# ESP32-P4 register map
Vendor: ESPRESSIF SYSTEMS (SHANGHAI) CO., LTD.; Series: ESP32 P-Series; File version: 3
CPU: RV32IMAFC r0p0, little endian, no MPU, FPU, 0 interrupt priority bits
Address unit: 32 bits
Registers are 32-bit, read-write, reset 0x0 unless marked. A register's access mark holds for its fields unless they carry their own. Offsets are from the block's base; [hi:lo] are bit positions; {n}, {i} and the like mark numbered series; <NAME> marks a mode.

## AXI_DMA — AXI_DMA Peripheral
Base 0x5008A000
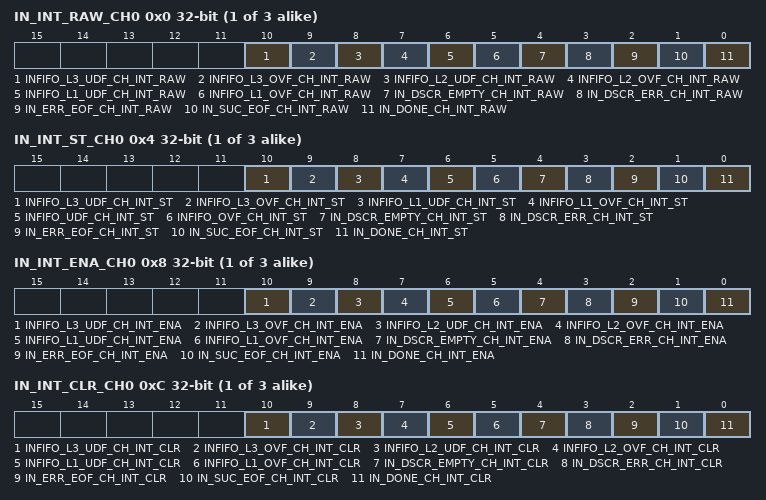
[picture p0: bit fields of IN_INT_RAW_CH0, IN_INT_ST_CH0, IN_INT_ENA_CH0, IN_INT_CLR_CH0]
{0x0+0x68*i} IN_INT_RAW_CH{i} (i=0..2) — Raw status interrupt of channel {i}
  [10] INFIFO_L3_UDF_CH_INT_RAW — This raw interrupt bit turns to high level when level 1 fifo of Rx channel 0 is underflow.
  [9] INFIFO_L3_OVF_CH_INT_RAW — This raw interrupt bit turns to high level when level 1 fifo of Rx channel 0 is overflow.
  [8] INFIFO_L2_UDF_CH_INT_RAW — This raw interrupt bit turns to high level when level 1 fifo of Rx channel 0 is underflow.
  [7] INFIFO_L2_OVF_CH_INT_RAW — This raw interrupt bit turns to high level when level 1 fifo of Rx channel 0 is overflow.
  [6] INFIFO_L1_UDF_CH_INT_RAW — This raw interrupt bit turns to high level when level 1 fifo of Rx channel 0 is underflow.
  [5] INFIFO_L1_OVF_CH_INT_RAW — This raw interrupt bit turns to high level when level 1 fifo of Rx channel 0 is overflow.
  [4] IN_DSCR_EMPTY_CH_INT_RAW — The raw interrupt bit turns to high level when Rx buffer pointed by inlink is full and receiving data is not completed but there is no more inlink for Rx channel 0.
  [3] IN_DSCR_ERR_CH_INT_RAW — The raw interrupt bit turns to high level when detecting inlink descriptor error including owner error and the second and third word error of inlink descriptor for Rx channel 0.
  [2] IN_ERR_EOF_CH_INT_RAW — The raw interrupt bit turns to high level when data error is detected only in the case that the peripheral is UHCI0 for Rx channel 0. For other peripherals this raw interrupt is reserved.
  [1] IN_SUC_EOF_CH_INT_RAW — The raw interrupt bit turns to high level when the last data pointed by one inlink descriptor has been received for Rx channel 0. For UHCI0 the raw interrupt bit turns to high level when the last data pointed by one inlink descriptor has been received and no data error is detected for Rx channel 0.
  [0] IN_DONE_CH_INT_RAW — The raw interrupt bit turns to high level when the last data pointed by one inlink descriptor has been received for Rx channel 0.
{0x4+0x68*i} IN_INT_ST_CH{i} (i=0..2) ro — Masked interrupt of channel {i}
  [10] INFIFO_L3_UDF_CH_INT_ST — The raw interrupt status bit for the INFIFO_UDF_L3_CH_INT interrupt.
  [9] INFIFO_L3_OVF_CH_INT_ST — The raw interrupt status bit for the INFIFO_OVF_L3_CH_INT interrupt.
  [8] INFIFO_L1_UDF_CH_INT_ST — The raw interrupt status bit for the INFIFO_UDF_L2_CH_INT interrupt.
  [7] INFIFO_L1_OVF_CH_INT_ST — The raw interrupt status bit for the INFIFO_OVF_L2_CH_INT interrupt.
  [6] INFIFO_UDF_CH_INT_ST — The raw interrupt status bit for the INFIFO_UDF_L1_CH_INT interrupt.
  [5] INFIFO_OVF_CH_INT_ST — The raw interrupt status bit for the INFIFO_OVF_L1_CH_INT interrupt.
  [4] IN_DSCR_EMPTY_CH_INT_ST — The raw interrupt status bit for the IN_DSCR_EMPTY_CH_INT interrupt.
  [3] IN_DSCR_ERR_CH_INT_ST — The raw interrupt status bit for the IN_DSCR_ERR_CH_INT interrupt.
  [2] IN_ERR_EOF_CH_INT_ST — The raw interrupt status bit for the IN_ERR_EOF_CH_INT interrupt.
  [1] IN_SUC_EOF_CH_INT_ST — The raw interrupt status bit for the IN_SUC_EOF_CH_INT interrupt.
  [0] IN_DONE_CH_INT_ST — The raw interrupt status bit for the IN_DONE_CH_INT interrupt.
{0x8+0x68*i} IN_INT_ENA_CH{i} (i=0..2) — Interrupt enable bits of channel {i}
  [10] INFIFO_L3_UDF_CH_INT_ENA — The interrupt enable bit for the INFIFO_UDF_L3_CH_INT interrupt.
  [9] INFIFO_L3_OVF_CH_INT_ENA — The interrupt enable bit for the INFIFO_OVF_L3_CH_INT interrupt.
  [8] INFIFO_L2_UDF_CH_INT_ENA — The interrupt enable bit for the INFIFO_UDF_L2_CH_INT interrupt.
  [7] INFIFO_L2_OVF_CH_INT_ENA — The interrupt enable bit for the INFIFO_OVF_L2_CH_INT interrupt.
  [6] INFIFO_L1_UDF_CH_INT_ENA — The interrupt enable bit for the INFIFO_UDF_L1_CH_INT interrupt.
  [5] INFIFO_L1_OVF_CH_INT_ENA — The interrupt enable bit for the INFIFO_OVF_L1_CH_INT interrupt.
  [4] IN_DSCR_EMPTY_CH_INT_ENA — The interrupt enable bit for the IN_DSCR_EMPTY_CH_INT interrupt.
  [3] IN_DSCR_ERR_CH_INT_ENA — The interrupt enable bit for the IN_DSCR_ERR_CH_INT interrupt.
  [2] IN_ERR_EOF_CH_INT_ENA — The interrupt enable bit for the IN_ERR_EOF_CH_INT interrupt.
  [1] IN_SUC_EOF_CH_INT_ENA — The interrupt enable bit for the IN_SUC_EOF_CH_INT interrupt.
  [0] IN_DONE_CH_INT_ENA — The interrupt enable bit for the IN_DONE_CH_INT interrupt.
{0xC+0x68*i} IN_INT_CLR_CH{i} (i=0..2) wo — Interrupt clear bits of channel {i}
  [10] INFIFO_L3_UDF_CH_INT_CLR — Set this bit to clear the INFIFO_UDF_L3_CH_INT interrupt.
  [9] INFIFO_L3_OVF_CH_INT_CLR — Set this bit to clear the INFIFO_OVF_L3_CH_INT interrupt.
  [8] INFIFO_L2_UDF_CH_INT_CLR — Set this bit to clear the INFIFO_UDF_L2_CH_INT interrupt.
  [7] INFIFO_L2_OVF_CH_INT_CLR — Set this bit to clear the INFIFO_OVF_L2_CH_INT interrupt.
  [6] INFIFO_L1_UDF_CH_INT_CLR — Set this bit to clear the INFIFO_UDF_L1_CH_INT interrupt.
  [5] INFIFO_L1_OVF_CH_INT_CLR — Set this bit to clear the INFIFO_OVF_L1_CH_INT interrupt.
  [4] IN_DSCR_EMPTY_CH_INT_CLR — Set this bit to clear the IN_DSCR_EMPTY_CH_INT interrupt.
  [3] IN_DSCR_ERR_CH_INT_CLR — Set this bit to clear the IN_DSCR_ERR_CH_INT interrupt.
  [2] IN_ERR_EOF_CH_INT_CLR — Set this bit to clear the IN_ERR_EOF_CH_INT interrupt.
  [1] IN_SUC_EOF_CH_INT_CLR — Set this bit to clear the IN_SUC_EOF_CH_INT interrupt.
  [0] IN_DONE_CH_INT_CLR — Set this bit to clear the IN_DONE_CH_INT interrupt.
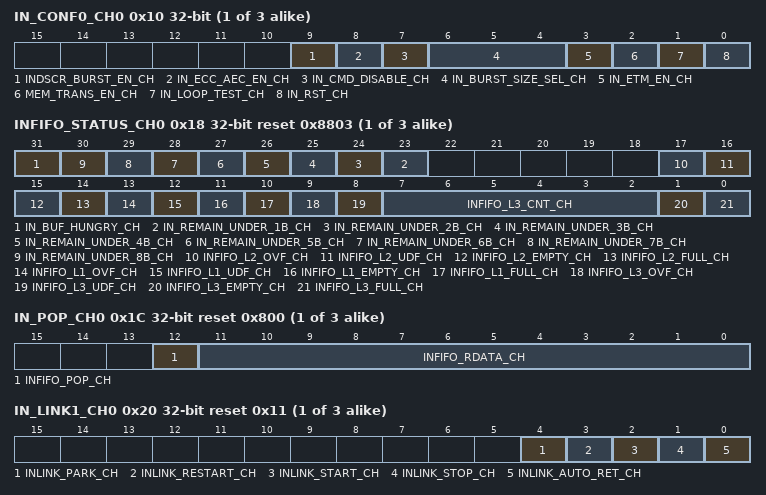
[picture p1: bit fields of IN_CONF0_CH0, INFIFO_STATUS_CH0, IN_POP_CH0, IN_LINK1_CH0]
{0x10+0x68*i} IN_CONF0_CH{i} (i=0..2) — Configure 0 register of Rx channel {i}
  [9] INDSCR_BURST_EN_CH — Set this bit to 1 to enable INCR burst transfer for Rx channel 0 reading link descriptor when accessing internal SRAM.
  [8] IN_ECC_AEC_EN_CH — 1: mean access ecc or aes domain,0: mean not
  [7] IN_CMD_DISABLE_CH — 1:mean disable cmd of this ch0
  [6:4] IN_BURST_SIZE_SEL_CH — 3'b000-3'b100:burst length 8byte~128byte
  [3] IN_ETM_EN_CH — Set this bit to 1 to enable etm control mode, dma Rx channel 0 is triggered by etm task.
  [2] MEM_TRANS_EN_CH — Set this bit 1 to enable automatic transmitting data from memory to memory via AXI_DMA.
  [1] IN_LOOP_TEST_CH — reserved
  [0] IN_RST_CH — This bit is used to reset AXI_DMA channel 0 Rx FSM and Rx FIFO pointer.
{0x14+0x68*i} IN_CONF1_CH{i} (i=0..2) — Configure 1 register of Rx channel {i}
  [12] IN_CHECK_OWNER_CH — Set this bit to enable checking the owner attribute of the link descriptor.
{0x18+0x68*i} INFIFO_STATUS_CH{i} (i=0..2) ro reset 0x8803 — Receive FIFO status of Rx channel {i}
  [31] IN_BUF_HUNGRY_CH — reserved
  [n+22] IN_REMAIN_UNDER_{n}B_CH (n=1..8) — reserved
  [17] INFIFO_L2_OVF_CH — L2 Rx FIFO over flow signal for Rx channel 0.
  [16] INFIFO_L2_UDF_CH — L2 Rx FIFO under flow signal for Rx channel 0.
  [15] INFIFO_L2_EMPTY_CH — L2 Rx RAM empty signal for Rx channel 0.
  [14] INFIFO_L2_FULL_CH — L2 Rx RAM full signal for Rx channel 0.
  [13] INFIFO_L1_OVF_CH — L1 Rx FIFO over flow signal for Rx channel 0.
  [12] INFIFO_L1_UDF_CH — L1 Rx FIFO under flow signal for Rx channel 0.
  [11] INFIFO_L1_EMPTY_CH — L1 Rx FIFO empty signal for Rx channel 0.
  [10] INFIFO_L1_FULL_CH — L1 Rx FIFO full signal for Rx channel 0.
  [9] INFIFO_L3_OVF_CH — L3 Rx FIFO over flow signal for Rx channel 0.
  [8] INFIFO_L3_UDF_CH — L3 Rx FIFO under flow signal for Rx channel 0.
  [7:2] INFIFO_L3_CNT_CH — The register stores the byte number of the data in L3 Rx FIFO for Rx channel 0.
  [1] INFIFO_L3_EMPTY_CH — L3 Rx FIFO empty signal for Rx channel 0.
  [0] INFIFO_L3_FULL_CH — L3 Rx FIFO full signal for Rx channel 0.
{0x1C+0x68*i} IN_POP_CH{i} (i=0..2) access per field reset 0x800 — Pop control register of Rx channel {i}
  [12] INFIFO_POP_CH wo — Set this bit to pop data from AXI_DMA FIFO.
  [11:0] INFIFO_RDATA_CH ro — This register stores the data popping from AXI_DMA FIFO.
{0x20+0x68*i} IN_LINK1_CH{i} (i=0..2) access per field reset 0x11 — Link descriptor configure and control register of Rx channel {i}
  [4] INLINK_PARK_CH ro — 1: the inlink descriptor's FSM is in idle state. 0: the inlink descriptor's FSM is working.
  [3] INLINK_RESTART_CH wo — Set this bit to mount a new inlink descriptor.
  [2] INLINK_START_CH wo — Set this bit to start dealing with the inlink descriptors.
  [1] INLINK_STOP_CH wo — Set this bit to stop dealing with the inlink descriptors.
  [0] INLINK_AUTO_RET_CH rw — Set this bit to return to current inlink descriptor's address when there are some errors in current receiving data.
{0x24+0x68*i} IN_LINK2_CH{i} (i=0..2) — Link descriptor configure and control register of Rx channel {i}
  [31:0] INLINK_ADDR_CH — This register stores the 20 least significant bits of the first inlink descriptor's address.
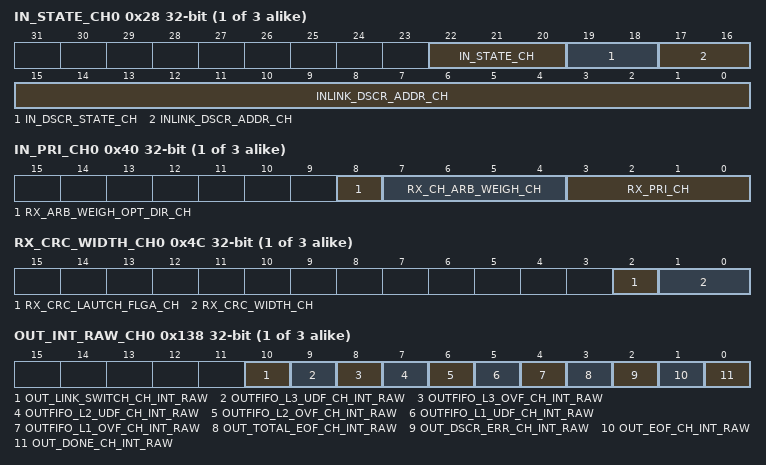
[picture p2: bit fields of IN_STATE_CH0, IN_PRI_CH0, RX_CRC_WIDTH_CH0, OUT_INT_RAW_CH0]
{0x28+0x68*i} IN_STATE_CH{i} (i=0..2) ro — Receive status of Rx channel {i}
  [22:20] IN_STATE_CH — reserved
  [19:18] IN_DSCR_STATE_CH — reserved
  [17:0] INLINK_DSCR_ADDR_CH — This register stores the current inlink descriptor's address.
{0x2C+0x68*i} IN_SUC_EOF_DES_ADDR_CH{i} (i=0..2) ro — Inlink descriptor address when EOF occurs of Rx channel {i}
  [31:0] IN_SUC_EOF_DES_ADDR_CH — This register stores the address of the inlink descriptor when the EOF bit in this descriptor is 1.
{0x30+0x68*i} IN_ERR_EOF_DES_ADDR_CH{i} (i=0..2) ro — Inlink descriptor address when errors occur of Rx channel {i}
  [31:0] IN_ERR_EOF_DES_ADDR_CH — This register stores the address of the inlink descriptor when there are some errors in current receiving data. Only used when peripheral is UHCI0.
{0x34+0x68*i} IN_DSCR_CH{i} (i=0..2) ro — Current inlink descriptor address of Rx channel {i}
  [31:0] INLINK_DSCR_CH — The address of the current inlink descriptor x.
{0x38+0x68*i} IN_DSCR_BF0_CH{i} (i=0..2) ro — The last inlink descriptor address of Rx channel {i}
  [31:0] INLINK_DSCR_BF0_CH — The address of the last inlink descriptor x-1.
{0x3C+0x68*i} IN_DSCR_BF1_CH{i} (i=0..2) ro — The second-to-last inlink descriptor address of Rx channel {i}
  [31:0] INLINK_DSCR_BF1_CH — The address of the second-to-last inlink descriptor x-2.
{0x40+0x68*i} IN_PRI_CH{i} (i=0..2) — Priority register of Rx channel {i}
  [8] RX_ARB_WEIGH_OPT_DIR_CH — 0: mean not optimazation weight function ,1: mean optimazation
  [7:4] RX_CH_ARB_WEIGH_CH — The weight of Rx channel 0
  [3:0] RX_PRI_CH — The priority of Rx channel 0. The larger of the value the higher of the priority.
{0x44+0x68*i} IN_PERI_SEL_CH{i} (i=0..2) reset 0x3F — Peripheral selection of Rx channel {i}
  [5:0] PERI_IN_SEL_CH — This register is used to select peripheral for Rx channel 0. 0:lcdcam. 1: gpspi_2. 2: gpspi_3. 3: parl_io. 4: aes. 5: sha. 6~15: Dummy
{0x48+0x68*i} IN_CRC_INIT_DATA_CH{i} (i=0..2) reset 0xFFFFFFFF — This register is used to config ch{i} crc initial data(max 32 bit)
  [31:0] IN_CRC_INIT_DATA_CH — This register is used to config ch0 of rx crc initial value
{0x4C+0x68*i} RX_CRC_WIDTH_CH{i} (i=0..2) — This register is used to confiig rx ch{i} crc result width,2'b00 mean crc_width <=8bit,2'b01 8<crc_width<=16 ,2'b10 mean 16<crc_width <=24,2'b11 mean 24<crc_width<=32
  [2] RX_CRC_LAUTCH_FLGA_CH — reserved
  [1:0] RX_CRC_WIDTH_CH — reserved
{0x50+0x68*i} IN_CRC_CLEAR_CH{i} (i=0..2) — This register is used to clear ch{i} crc result
  [0] IN_CRC_CLEAR_CH — This register is used to clear ch0 of rx crc result
{0x54+0x68*i} IN_CRC_FINAL_RESULT_CH{i} (i=0..2) ro — This register is used to store ch{i} crc result
  [31:0] IN_CRC_FINAL_RESULT_CH — This register is used to store result ch0 of rx
{0x58+0x68*i} RX_CRC_EN_WR_DATA_CH{i} (i=0..2) — This resister is used to config ch{i} crc en for every bit
  [31:0] RX_CRC_EN_WR_DATA_CH — This register is used to enable rx ch0 crc 32bit on/off
{0x5C+0x68*i} RX_CRC_EN_ADDR_CH{i} (i=0..2) — This register is used to config ch{i} crc en addr
  [31:0] RX_CRC_EN_ADDR_CH — reserved
{0x60+0x68*i} RX_CRC_DATA_EN_WR_DATA_CH{i} (i=0..2) — This register is used to config crc data_8bit en
  [15:0] RX_CRC_DATA_EN_WR_DATA_CH — reserved
{0x64+0x68*i} RX_CRC_DATA_EN_ADDR_CH{i} (i=0..2) — This register is used to config addr of crc data_8bit en
  [31:0] RX_CRC_DATA_EN_ADDR_CH — reserved
{0x138+0x68*i} OUT_INT_RAW_CH{i} (i=0..2) — Raw status interrupt of channel{i}
  [10] OUT_LINK_SWITCH_CH_INT_RAW — The raw interrupt bit turns to high level when the dma switch to new link for Tx channel0.
  [9] OUTFIFO_L3_UDF_CH_INT_RAW — This raw interrupt bit turns to high level when level 1 fifo of Tx channel0 is underflow.
  [8] OUTFIFO_L3_OVF_CH_INT_RAW — This raw interrupt bit turns to high level when level 1 fifo of Tx channel0 is overflow.
  [7] OUTFIFO_L2_UDF_CH_INT_RAW — This raw interrupt bit turns to high level when level 1 fifo of Tx channel0 is underflow.
  [6] OUTFIFO_L2_OVF_CH_INT_RAW — This raw interrupt bit turns to high level when level 1 fifo of Tx channel0 is overflow.
  [5] OUTFIFO_L1_UDF_CH_INT_RAW — This raw interrupt bit turns to high level when level 1 fifo of Tx channel0 is underflow.
  [4] OUTFIFO_L1_OVF_CH_INT_RAW — This raw interrupt bit turns to high level when level 1 fifo of Tx channel0 is overflow.
  [3] OUT_TOTAL_EOF_CH_INT_RAW — The raw interrupt bit turns to high level when data corresponding a outlink (includes one link descriptor or few link descriptors) is transmitted out for Tx channel0.
  [2] OUT_DSCR_ERR_CH_INT_RAW — The raw interrupt bit turns to high level when detecting outlink descriptor error including owner error and the second and third word error of outlink descriptor for Tx channel0.
  [1] OUT_EOF_CH_INT_RAW — The raw interrupt bit turns to high level when the last data pointed by one outlink descriptor has been read from memory for Tx channel0.
  [0] OUT_DONE_CH_INT_RAW — The raw interrupt bit turns to high level when the last data pointed by one outlink descriptor has been transmitted to peripherals for Tx channel0.
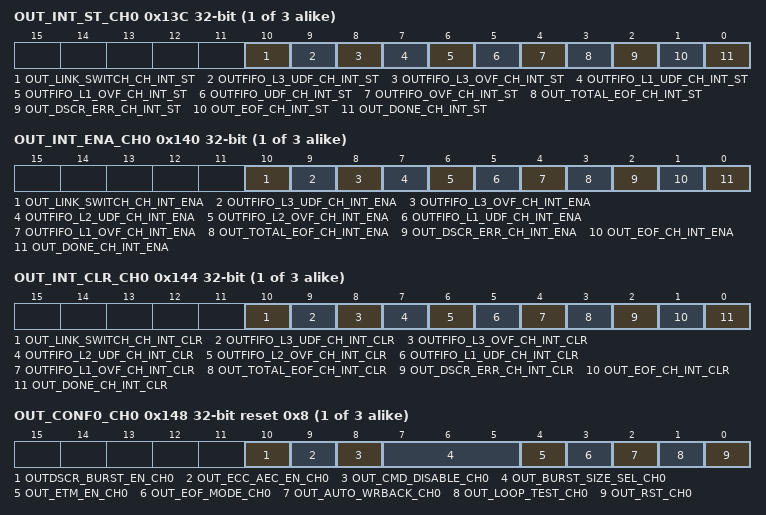
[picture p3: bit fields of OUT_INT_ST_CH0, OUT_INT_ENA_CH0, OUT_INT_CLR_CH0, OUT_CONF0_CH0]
{0x13C+0x68*i} OUT_INT_ST_CH{i} (i=0..2) ro — Masked interrupt of channel{i}
  [10] OUT_LINK_SWITCH_CH_INT_ST — The raw interrupt status bit for the OUT_LINK_SWITCH_CH_INT interrupt.
  [9] OUTFIFO_L3_UDF_CH_INT_ST — The raw interrupt status bit for the OUTFIFO_UDF_L3_CH_INT interrupt.
  [8] OUTFIFO_L3_OVF_CH_INT_ST — The raw interrupt status bit for the OUTFIFO_OVF_L3_CH_INT interrupt.
  [7] OUTFIFO_L1_UDF_CH_INT_ST — The raw interrupt status bit for the OUTFIFO_UDF_L2_CH_INT interrupt.
  [6] OUTFIFO_L1_OVF_CH_INT_ST — The raw interrupt status bit for the OUTFIFO_OVF_L2_CH_INT interrupt.
  [5] OUTFIFO_UDF_CH_INT_ST — The raw interrupt status bit for the OUTFIFO_UDF_L1_CH_INT interrupt.
  [4] OUTFIFO_OVF_CH_INT_ST — The raw interrupt status bit for the OUTFIFO_OVF_L1_CH_INT interrupt.
  [3] OUT_TOTAL_EOF_CH_INT_ST — The raw interrupt status bit for the OUT_TOTAL_EOF_CH_INT interrupt.
  [2] OUT_DSCR_ERR_CH_INT_ST — The raw interrupt status bit for the OUT_DSCR_ERR_CH_INT interrupt.
  [1] OUT_EOF_CH_INT_ST — The raw interrupt status bit for the OUT_EOF_CH_INT interrupt.
  [0] OUT_DONE_CH_INT_ST — The raw interrupt status bit for the OUT_DONE_CH_INT interrupt.
{0x140+0x68*i} OUT_INT_ENA_CH{i} (i=0..2) — Interrupt enable bits of channel{i}
  [10] OUT_LINK_SWITCH_CH_INT_ENA — The interrupt enable bit for the OUT_LINK_SWITCH_CH_INT interrupt.
  [9] OUTFIFO_L3_UDF_CH_INT_ENA — The interrupt enable bit for the OUTFIFO_UDF_L3_CH_INT interrupt.
  [8] OUTFIFO_L3_OVF_CH_INT_ENA — The interrupt enable bit for the OUTFIFO_OVF_L3_CH_INT interrupt.
  [7] OUTFIFO_L2_UDF_CH_INT_ENA — The interrupt enable bit for the OUTFIFO_UDF_L2_CH_INT interrupt.
  [6] OUTFIFO_L2_OVF_CH_INT_ENA — The interrupt enable bit for the OUTFIFO_OVF_L2_CH_INT interrupt.
  [5] OUTFIFO_L1_UDF_CH_INT_ENA — The interrupt enable bit for the OUTFIFO_UDF_L1_CH_INT interrupt.
  [4] OUTFIFO_L1_OVF_CH_INT_ENA — The interrupt enable bit for the OUTFIFO_OVF_L1_CH_INT interrupt.
  [3] OUT_TOTAL_EOF_CH_INT_ENA — The interrupt enable bit for the OUT_TOTAL_EOF_CH_INT interrupt.
  [2] OUT_DSCR_ERR_CH_INT_ENA — The interrupt enable bit for the OUT_DSCR_ERR_CH_INT interrupt.
  [1] OUT_EOF_CH_INT_ENA — The interrupt enable bit for the OUT_EOF_CH_INT interrupt.
  [0] OUT_DONE_CH_INT_ENA — The interrupt enable bit for the OUT_DONE_CH_INT interrupt.
{0x144+0x68*i} OUT_INT_CLR_CH{i} (i=0..2) wo — Interrupt clear bits of channel{i}
  [10] OUT_LINK_SWITCH_CH_INT_CLR — Set this bit to clear the OUT_LINK_SWITCH_CH_INT interrupt.
  [9] OUTFIFO_L3_UDF_CH_INT_CLR — Set this bit to clear the OUTFIFO_UDF_L3_CH_INT interrupt.
  [8] OUTFIFO_L3_OVF_CH_INT_CLR — Set this bit to clear the OUTFIFO_OVF_L3_CH_INT interrupt.
  [7] OUTFIFO_L2_UDF_CH_INT_CLR — Set this bit to clear the OUTFIFO_UDF_L2_CH_INT interrupt.
  [6] OUTFIFO_L2_OVF_CH_INT_CLR — Set this bit to clear the OUTFIFO_OVF_L2_CH_INT interrupt.
  [5] OUTFIFO_L1_UDF_CH_INT_CLR — Set this bit to clear the OUTFIFO_UDF_L1_CH_INT interrupt.
  [4] OUTFIFO_L1_OVF_CH_INT_CLR — Set this bit to clear the OUTFIFO_OVF_L1_CH_INT interrupt.
  [3] OUT_TOTAL_EOF_CH_INT_CLR — Set this bit to clear the OUT_TOTAL_EOF_CH_INT interrupt.
  [2] OUT_DSCR_ERR_CH_INT_CLR — Set this bit to clear the OUT_DSCR_ERR_CH_INT interrupt.
  [1] OUT_EOF_CH_INT_CLR — Set this bit to clear the OUT_EOF_CH_INT interrupt.
  [0] OUT_DONE_CH_INT_CLR — Set this bit to clear the OUT_DONE_CH_INT interrupt.
{0x148+0x68*i} OUT_CONF0_CH{i} reset 0x8 (i=0..2) — Configure 0 register of Tx channel{i}
  [10] OUTDSCR_BURST_EN_CH{i} — Set this bit to 1 to enable INCR burst transfer for Tx channel{i} reading link descriptor when accessing internal SRAM.
  [9] OUT_ECC_AEC_EN_CH{i} — 1: mean access ecc or aes domain,0: mean not
  [8] OUT_CMD_DISABLE_CH{i} — 1:mean disable cmd of this ch{i}
  [7:5] OUT_BURST_SIZE_SEL_CH{i} — 3'b000-3'b100:burst length 8byte~128byte
  [4] OUT_ETM_EN_CH{i} — Set this bit to 1 to enable etm control mode, dma Tx channel{i} is triggered by etm task.
  [3] OUT_EOF_MODE_CH{i} — EOF flag generation mode when transmitting data. 1: EOF flag for Tx channel{i} is generated when data need to transmit has been popped from FIFO in AXI_DMA
  [2] OUT_AUTO_WRBACK_CH{i} — Set this bit to enable automatic outlink-writeback when all the data in tx buffer has been transmitted.
  [1] OUT_LOOP_TEST_CH{i} — reserved
  [0] OUT_RST_CH{i} — This bit is used to reset AXI_DMA channel{i} Tx FSM and Tx FIFO pointer.
{0x14C+0x68*i} OUT_CONF1_CH{i} (i=0..2) — Configure 1 register of Tx channel{i}
  [12] OUT_CHECK_OWNER_CH — Set this bit to enable checking the owner attribute of the link descriptor.
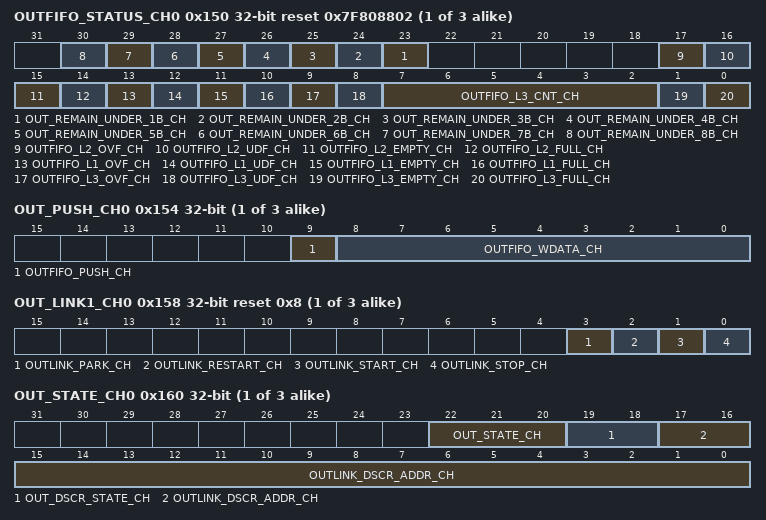
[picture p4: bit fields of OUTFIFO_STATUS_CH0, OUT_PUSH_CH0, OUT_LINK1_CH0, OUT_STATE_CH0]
{0x150+0x68*i} OUTFIFO_STATUS_CH{i} (i=0..2) ro reset 0x7F808802 — Transmit FIFO status of Tx channel{i}
  [n+22] OUT_REMAIN_UNDER_{n}B_CH (n=1..8) — reserved
  [17] OUTFIFO_L2_OVF_CH — L2 Tx FIFO over flow signal for Tx channel0.
  [16] OUTFIFO_L2_UDF_CH — L2 Tx FIFO under flow signal for Tx channel0.
  [15] OUTFIFO_L2_EMPTY_CH — L2 Tx RAM empty signal for Tx channel0.
  [14] OUTFIFO_L2_FULL_CH — L2 Tx RAM full signal for Tx channel0.
  [13] OUTFIFO_L1_OVF_CH — L1 Tx FIFO over flow signal for Tx channel0.
  [12] OUTFIFO_L1_UDF_CH — L1 Tx FIFO under flow signal for Tx channel0.
  [11] OUTFIFO_L1_EMPTY_CH — L1 Tx FIFO empty signal for Tx channel0.
  [10] OUTFIFO_L1_FULL_CH — L1 Tx FIFO full signal for Tx channel0.
  [9] OUTFIFO_L3_OVF_CH — L3 Tx FIFO over flow signal for Tx channel0.
  [8] OUTFIFO_L3_UDF_CH — L3 Tx FIFO under flow signal for Tx channel0.
  [7:2] OUTFIFO_L3_CNT_CH — The register stores the byte number of the data in L3 Tx FIFO for Tx channel0.
  [1] OUTFIFO_L3_EMPTY_CH — L3 Tx FIFO empty signal for Tx channel0.
  [0] OUTFIFO_L3_FULL_CH — L3 Tx FIFO full signal for Tx channel0.
{0x154+0x68*i} OUT_PUSH_CH{i} (i=0..2) access per field — Push control register of Tx channel{i}
  [9] OUTFIFO_PUSH_CH wo — Set this bit to push data into AXI_DMA FIFO.
  [8:0] OUTFIFO_WDATA_CH rw — This register stores the data that need to be pushed into AXI_DMA FIFO.
{0x158+0x68*i} OUT_LINK1_CH{i} (i=0..2) access per field reset 0x8 — Link descriptor configure and control register of Tx channel{i}
  [3] OUTLINK_PARK_CH ro — 1: the outlink descriptor's FSM is in idle state. 0: the outlink descriptor's FSM is working.
  [2] OUTLINK_RESTART_CH wo — Set this bit to restart a new outlink from the last address.
  [1] OUTLINK_START_CH wo — Set this bit to start dealing with the outlink descriptors.
  [0] OUTLINK_STOP_CH wo — Set this bit to stop dealing with the outlink descriptors.
{0x15C+0x68*i} OUT_LINK2_CH{i} (i=0..2) — Link descriptor configure and control register of Tx channel{i}
  [31:0] OUTLINK_ADDR_CH — This register stores the 32 least significant bits of the first outlink descriptor's address.
{0x160+0x68*i} OUT_STATE_CH{i} (i=0..2) ro — Transmit status of Tx channel{i}
  [22:20] OUT_STATE_CH — reserved
  [19:18] OUT_DSCR_STATE_CH — reserved
  [17:0] OUTLINK_DSCR_ADDR_CH — This register stores the current outlink descriptor's address.
{0x164+0x68*i} OUT_EOF_DES_ADDR_CH{i} (i=0..2) ro — Outlink descriptor address when EOF occurs of Tx channel{i}
  [31:0] OUT_EOF_DES_ADDR_CH — This register stores the address of the outlink descriptor when the EOF bit in this descriptor is 1.
{0x168+0x68*i} OUT_EOF_BFR_DES_ADDR_CH{i} (i=0..2) ro — The last outlink descriptor address when EOF occurs of Tx channel{i}
  [31:0] OUT_EOF_BFR_DES_ADDR_CH — This register stores the address of the outlink descriptor before the last outlink descriptor.
{0x16C+0x68*i} OUT_DSCR_CH{i} (i=0..2) ro — Current outlink descriptor address of Tx channel{i}
  [31:0] OUTLINK_DSCR_CH — The address of the current outlink descriptor y.
{0x170+0x68*i} OUT_DSCR_BF0_CH{i} (i=0..2) ro — The last outlink descriptor address of Tx channel{i}
  [31:0] OUTLINK_DSCR_BF0_CH — The address of the last outlink descriptor y-1.
{0x174+0x68*i} OUT_DSCR_BF1_CH{i} (i=0..2) ro — The second-to-last outlink descriptor address of Tx channel{i}
  [31:0] OUTLINK_DSCR_BF1_CH — The address of the second-to-last outlink descriptor x-2.
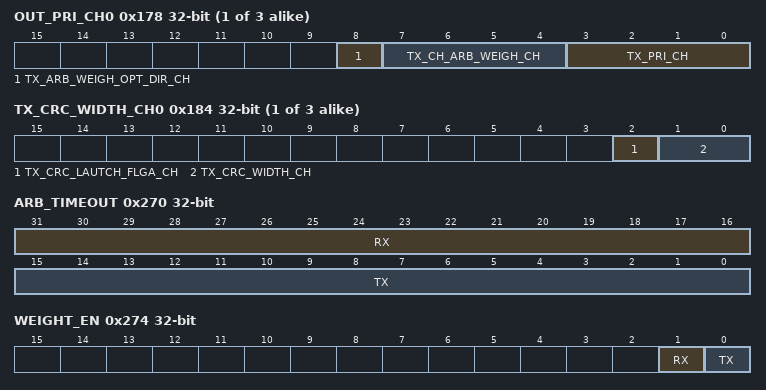
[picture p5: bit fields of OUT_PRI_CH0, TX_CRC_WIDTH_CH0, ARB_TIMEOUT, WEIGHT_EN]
{0x178+0x68*i} OUT_PRI_CH{i} (i=0..2) — Priority register of Tx channel{i}.
  [8] TX_ARB_WEIGH_OPT_DIR_CH — 0: mean not optimazation weight function ,1: mean optimazation
  [7:4] TX_CH_ARB_WEIGH_CH — The weight of Tx channel0
  [3:0] TX_PRI_CH — The priority of Tx channel0. The larger of the value the higher of the priority.
{0x17C+0x68*i} OUT_PERI_SEL_CH{i} (i=0..2) reset 0x3F — Peripheral selection of Tx channel{i}
  [5:0] PERI_OUT_SEL_CH — This register is used to select peripheral for Tx channel0. 0:lcdcam. 1: gpspi_2. 2: gpspi_3. 3: parl_io. 4: aes. 5: sha. 6~15: Dummy
{0x180+0x68*i} OUT_CRC_INIT_DATA_CH{i} (i=0..2) reset 0xFFFFFFFF — This register is used to config ch{i} crc initial data(max 32 bit)
  [31:0] OUT_CRC_INIT_DATA_CH — This register is used to config ch0 of tx crc initial value
{0x184+0x68*i} TX_CRC_WIDTH_CH{i} (i=0..2) — This register is used to confiig tx ch{i} crc result width,2'b00 mean crc_width <=8bit,2'b01 8<crc_width<=16 ,2'b10 mean 16<crc_width <=24,2'b11 mean 24<crc_width<=32
  [2] TX_CRC_LAUTCH_FLGA_CH — reserved
  [1:0] TX_CRC_WIDTH_CH — reserved
{0x188+0x68*i} OUT_CRC_CLEAR_CH{i} (i=0..2) — This register is used to clear ch{i} crc result
  [0] OUT_CRC_CLEAR_CH — This register is used to clear ch0 of tx crc result
{0x18C+0x68*i} OUT_CRC_FINAL_RESULT_CH{i} (i=0..2) ro — This register is used to store ch{i} crc result
  [31:0] OUT_CRC_FINAL_RESULT_CH — This register is used to store result ch0 of tx
{0x190+0x68*i} TX_CRC_EN_WR_DATA_CH{i} (i=0..2) — This resister is used to config ch{i} crc en for every bit
  [31:0] TX_CRC_EN_WR_DATA_CH — This register is used to enable tx ch0 crc 32bit on/off
{0x194+0x68*i} TX_CRC_EN_ADDR_CH{i} (i=0..2) — This register is used to config ch{i} crc en addr
  [31:0] TX_CRC_EN_ADDR_CH — reserved
{0x198+0x68*i} TX_CRC_DATA_EN_WR_DATA_CH{i} (i=0..2) — This register is used to config crc data_8bit en
  [15:0] TX_CRC_DATA_EN_WR_DATA_CH — reserved
{0x19C+0x68*i} TX_CRC_DATA_EN_ADDR_CH{i} (i=0..2) — This register is used to config addr of crc data_8bit en
  [31:0] TX_CRC_DATA_EN_ADDR_CH — reserved
0x270 ARB_TIMEOUT — This retister is used to config arbiter time slice
  [31:16] RX — This register is used to config rx arbiter time out value
  [15:0] TX — This register is used to config tx arbiter time out value
0x274 WEIGHT_EN — This register is used to config arbiter weight function to on or off
  [1] RX — This register is used to config rx arbiter weight function off/on
  [0] TX — This register is used to config tx arbiter weight function off/on
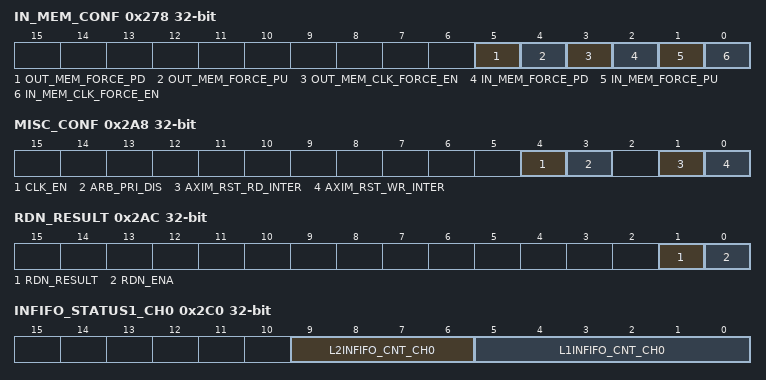
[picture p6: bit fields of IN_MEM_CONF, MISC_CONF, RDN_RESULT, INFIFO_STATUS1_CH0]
0x278 IN_MEM_CONF — Mem power configure register of Rx channel
  [5] OUT_MEM_FORCE_PD — Force power down ram
  [4] OUT_MEM_FORCE_PU — Force power up ram
  [3] OUT_MEM_CLK_FORCE_EN — 1: Force to open the clock and bypass the gate-clock when accessing the RAM in AXI_DMA. 0: A gate-clock will be used when accessing the RAM in AXI_DMA.
  [2] IN_MEM_FORCE_PD — Force power down ram
  [1] IN_MEM_FORCE_PU — Force power up ram
  [0] IN_MEM_CLK_FORCE_EN — 1: Force to open the clock and bypass the gate-clock when accessing the RAM in AXI_DMA. 0: A gate-clock will be used when accessing the RAM in AXI_DMA.
0x27C INTR_MEM_START_ADDR reset 0x30100000 — The start address of accessible address space.
  [31:0] ACCESS_INTR_MEM_START_ADDR
0x280 INTR_MEM_END_ADDR reset 0x8FFFFFFF — The end address of accessible address space. The access address beyond this range would lead to descriptor error.
  [31:0] ACCESS_INTR_MEM_END_ADDR
0x284 EXTR_MEM_START_ADDR reset 0x30100000 — The start address of accessible address space.
  [31:0] ACCESS_EXTR_MEM_START_ADDR
0x288 EXTR_MEM_END_ADDR reset 0x8FFFFFFF — The end address of accessible address space. The access address beyond this range would lead to descriptor error.
  [31:0] ACCESS_EXTR_MEM_END_ADDR
{0x28C+4i} IN_RESET_AVAIL_CH{i} (i=0..2) ro reset 0x1 — The rx channel {i} reset valid_flag register.
  [0] IN_RESET_AVAIL_CH — rx chan0 reset valid reg.
{0x298+4i} OUT_RESET_AVAIL_CH{i} (i=0..2) ro reset 0x1 — The tx channel {i} reset valid_flag register.
  [0] OUT_RESET_AVAIL_CH — tx chan0 reset valid reg.
0x2A8 MISC_CONF — MISC register
  [4] CLK_EN — 1'h1: Force clock on for register. 1'h0: Support clock only when application writes registers.
  [3] ARB_PRI_DIS — Set this bit to disable priority arbitration function.
  [1] AXIM_RST_RD_INTER — Set this bit then clear this bit to reset the internal axi_rd FSM.
  [0] AXIM_RST_WR_INTER — Set this bit then clear this bit to reset the internal axi_wr FSM.
0x2AC RDN_RESULT access per field — reserved
  [1] RDN_RESULT ro — reserved
  [0] RDN_ENA rw — reserved
0x2B0 RDN_ECO_HIGH reset 0xFFFFFFFF — reserved
  [31:0] RDN_ECO_HIGH — The start address of accessible address space.
0x2B4 RDN_ECO_LOW — reserved
  [31:0] RDN_ECO_LOW — The start address of accessible address space.
0x2B8 WRESP_CNT ro — AXI wr responce cnt register.
  [3:0] WRESP_CNT — axi wr responce cnt reg.
0x2BC RRESP_CNT ro — AXI wr responce cnt register.
  [3:0] RRESP_CNT — axi rd responce cnt reg.
0x2C0 INFIFO_STATUS1_CH0 ro — Receive FIFO status of Rx channel 0
  [9:6] L2INFIFO_CNT_CH0 — The register stores the byte number of the data in L2 Rx FIFO for Rx channel 0.
  [5:0] L1INFIFO_CNT_CH0 — The register stores the byte number of the data in L1 Rx FIFO for Rx channel 0.
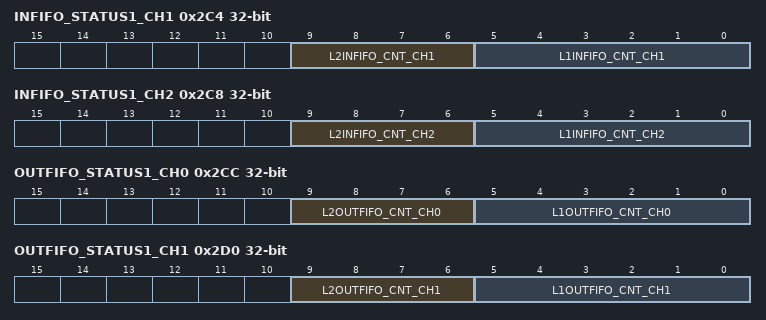
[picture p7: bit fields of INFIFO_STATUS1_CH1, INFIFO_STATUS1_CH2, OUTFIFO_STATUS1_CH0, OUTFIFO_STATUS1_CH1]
0x2C4 INFIFO_STATUS1_CH1 ro — Receive FIFO status of Rx channel 1
  [9:6] L2INFIFO_CNT_CH1 — The register stores the byte number of the data in L2 Rx FIFO for Rx channel 1.
  [5:0] L1INFIFO_CNT_CH1 — The register stores the byte number of the data in L1 Rx FIFO for Rx channel 1.
0x2C8 INFIFO_STATUS1_CH2 ro — Receive FIFO status of Rx channel 1
  [9:6] L2INFIFO_CNT_CH2 — The register stores the byte number of the data in L2 Rx FIFO for Rx channel 2.
  [5:0] L1INFIFO_CNT_CH2 — The register stores the byte number of the data in L1 Rx FIFO for Rx channel 2.
0x2CC OUTFIFO_STATUS1_CH0 ro — Receive FIFO status of Tx channel 0
  [9:6] L2OUTFIFO_CNT_CH0 — The register stores the byte number of the data in L2 Tx FIFO for Tx channel 0.
  [5:0] L1OUTFIFO_CNT_CH0 — The register stores the byte number of the data in L1 Tx FIFO for Tx channel 0.
0x2D0 OUTFIFO_STATUS1_CH1 ro — Receive FIFO status of Tx channel 1
  [9:6] L2OUTFIFO_CNT_CH1 — The register stores the byte number of the data in L2 Tx FIFO for Tx channel 1.
  [5:0] L1OUTFIFO_CNT_CH1 — The register stores the byte number of the data in L1 Tx FIFO for Tx channel 1.
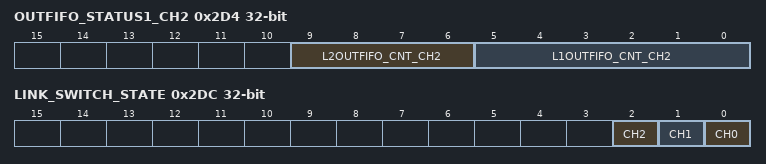
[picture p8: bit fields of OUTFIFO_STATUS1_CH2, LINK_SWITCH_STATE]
0x2D4 OUTFIFO_STATUS1_CH2 ro — Receive FIFO status of Tx channel 1
  [9:6] L2OUTFIFO_CNT_CH2 — The register stores the byte number of the data in L2 Tx FIFO for Tx channel 2.
  [5:0] L1OUTFIFO_CNT_CH2 — The register stores the byte number of the data in L1 Tx FIFO for Tx channel 2.
0x2D8 DATE reset 0x2303140 — Version control register
  [31:0] DATE — register version.
0x2DC LINK_SWITCH_STATE — Version control register
  [2] CH2 — The register that confirm ch dscr switch success
  [1] CH1 — The register that confirm ch dscr switch success
  [0] CH0 — The register that confirm ch dscr switch success
